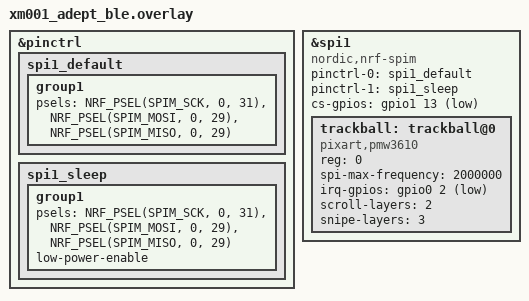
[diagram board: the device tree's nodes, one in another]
/*
 * XM001-Adept_BLE overlay: PMW3610 trackball bus and device.
 *
 * Net trace (PCB netlist -> E73 pad -> nRF pin):
 *   SCLK   sensor pad 3 -> E73 pad 9 -> P0.31
 *   SDIO   sensor pad 2 -> E73 pad 8 -> P0.29   (the "MOSI" net)
 *   MOTION sensor pad 8 -> E73 pad 7 -> P0.02   (the "MISO" net, used as IRQ)
 *   NCS    sensor pad 5 -> E73 pad 6 -> P1.13
 *
 * The PMW3610 has ONE bidirectional data pin (SDIO, pad 2); pad 8 is the
 * MOTION interrupt output.  So the SPI controller must shift data in and out
 * on the same pin: MOSI and MISO are both set to P0.29, exactly like the
 * working charybdis board (there MOSI and MISO are both P0.17).  P0.02
 * carries MOTION as the data-ready interrupt.
 *
 * SPDX-License-Identifier: MIT
 */

#include "xm001_adept_ble.dtsi"

&pinctrl {
	spi1_default: spi1_default {
		group1 {
			psels = <NRF_PSEL(SPIM_SCK, 0, 31)>,
				<NRF_PSEL(SPIM_MOSI, 0, 29)>,
				<NRF_PSEL(SPIM_MISO, 0, 29)>;
		};
	};

	spi1_sleep: spi1_sleep {
		group1 {
			psels = <NRF_PSEL(SPIM_SCK, 0, 31)>,
				<NRF_PSEL(SPIM_MOSI, 0, 29)>,
				<NRF_PSEL(SPIM_MISO, 0, 29)>;
			low-power-enable;
		};
	};
};

&spi1 {
	status = "okay";
	compatible = "nordic,nrf-spim";
	pinctrl-0 = <&spi1_default>;
	pinctrl-1 = <&spi1_sleep>;
	pinctrl-names = "default", "sleep";

	cs-gpios = <&gpio1 13 GPIO_ACTIVE_LOW>;

	trackball: trackball@0 {
		status = "okay";
		compatible = "pixart,pmw3610";
		reg = <0>;
		spi-max-frequency = <2000000>;
		irq-gpios = <&gpio0 2 (GPIO_ACTIVE_LOW | GPIO_PULL_UP)>;

		/* Layer indices into the keymap: 2 = scroll, 3 = snipe. */
		scroll-layers = <2>;
		snipe-layers = <3>;
	};
};
